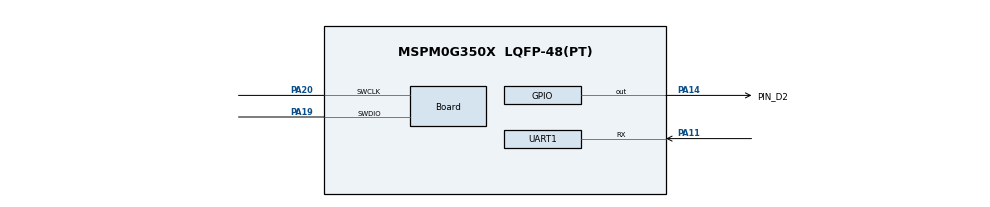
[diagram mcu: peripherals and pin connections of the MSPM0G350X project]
/**
 * @cliArgs --device "MSPM0G350X" --package "LQFP-48(PT)" --part "Default" --product "mspm0_sdk@2.01.00.03"
 * @versions {"tool":"1.20.0+3587"}
 */

/**
 * Import the modules used in this configuration.
 */
const GPIO          = scripting.addModule("/ti/driverlib/GPIO", {}, false);
const GPIO1         = GPIO.addInstance();
const SYSCTL        = scripting.addModule("/ti/driverlib/SYSCTL");
const UART          = scripting.addModule("/ti/driverlib/UART", {}, false);
const UART1         = UART.addInstance();
const ProjectConfig = scripting.addModule("/ti/project_config/ProjectConfig");

/**
 * Write custom configuration values to the imported modules.
 */
GPIO1.$name                          = "GPIO_LED";
GPIO1.associatedPins[0].assignedPort = "PORTA";
GPIO1.associatedPins[0].assignedPin  = "14";
GPIO1.associatedPins[0].$name        = "PIN_D2";
GPIO1.associatedPins[0].pin.$assign  = "PA14";

const Board                       = scripting.addModule("/ti/driverlib/Board", {}, false);
Board.peripheral.$assign          = "DEBUGSS";
Board.peripheral.swclkPin.$assign = "PA20";
Board.peripheral.swdioPin.$assign = "PA19";

SYSCTL.forceDefaultClkConfig = true;
SYSCTL.peripheral.$assign    = "SYSCTL";

UART1.$name                            = "UART_CH340";
UART1.targetBaudRate                   = 115200;
UART1.direction                        = "RX";
UART1.rxTimeoutValue                   = 1;
UART1.enabledInterrupts                = ["RX_TIMEOUT_ERROR"];
UART1.peripheral.$assign               = "UART0";
UART1.peripheral.rxPin.$assign         = "PA11";
UART1.rxPinConfig.$name                = "ti_driverlib_gpio_GPIOPinGeneric1";
UART1.rxPinConfig.hideOutputInversion  = scripting.forceWrite(false);
UART1.rxPinConfig.onlyInternalResistor = scripting.forceWrite(false);
UART1.rxPinConfig.passedPeripheralType = scripting.forceWrite("Digital");

ProjectConfig.deviceSpin = "MSPM0G3507";
